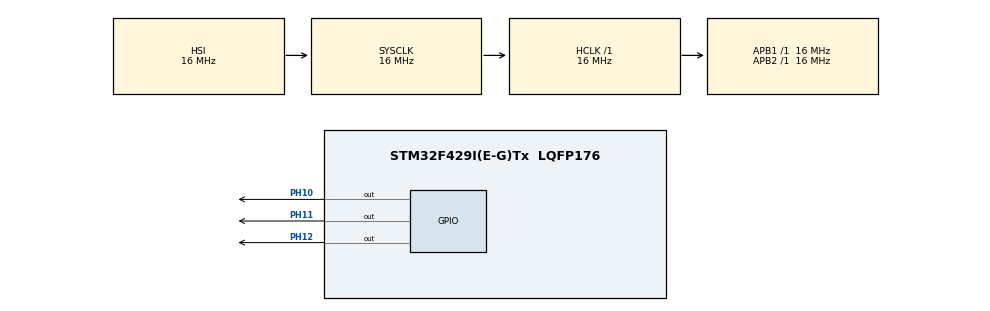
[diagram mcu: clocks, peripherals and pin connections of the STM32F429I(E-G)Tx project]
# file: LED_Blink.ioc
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Mcu.Family=STM32F4
Mcu.Name=STM32F429I(E-G)Tx
Mcu.Package=LQFP176
NVIC.PriorityGroup=NVIC_PRIORITYGROUP_4
PH10.Signal=GPIO_Output
PH11.Signal=GPIO_Output
PH12.Signal=GPIO_Output
ProjectManager.HeapSize=0x200
ProjectManager.StackSize=0x400
ProjectManager.TargetToolchain=STM32CubeIDE
RCC.AHBFreq_Value=16000000
RCC.APB1Freq_Value=16000000
RCC.APB2Freq_Value=16000000
RCC.CortexFreq_Value=16000000
RCC.HSE_VALUE=25000000
RCC.HSI_VALUE=16000000
RCC.LSE_VALUE=32768
RCC.SYSCLKFreq_VALUE=16000000
RCC.VCOOutputFreq_Value=192000000
board=custom

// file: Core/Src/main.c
/* USER CODE BEGIN Header */
/**
  ******************************************************************************
  * @file           : main.c
  * @brief          : Main program body
  ******************************************************************************
  * @attention
  *
  * Copyright (c) 2024 STMicroelectronics.
  * All rights reserved.
  *
  * This software is licensed under terms that can be found in the LICENSE file
  * in the root directory of this software component.
  * If no LICENSE file comes with this software, it is provided AS-IS.
  *
  ******************************************************************************
  */
/* USER CODE END Header */
#include "main.h"
#include "gpio.h"

/* USER CODE BEGIN PV */
uint32_t led1_cnt    = 0;
uint32_t led1_B      = 0;
uint32_t led1_isPlus = 0;

uint32_t led2_cnt    = 0;
uint32_t led2_B      = 0;
uint32_t led2_isPlus = 0;

uint32_t led3_cnt    = 0;
uint32_t led3_B      = 0;
uint32_t led3_isPlus = 0;

uint32_t delaycnt = 0;

/* USER CODE END PV */

void SystemClock_Config(void);

int main(void)
{

  /* MCU Configuration--------------------------------------------------------*/

  /* Reset of all peripherals, Initializes the Flash interface and the Systick. */
  HAL_Init();

  /* Configure the system clock */
  SystemClock_Config();

  /* Initialize all configured peripherals */
  MX_GPIO_Init();
  led1_B = 33;
  led2_B = 66;
  led3_B = 99;
  /* Infinite loop */
  while (1)
  {

    /* USER CODE BEGIN 3 */
	if(0) {
		HAL_GPIO_WritePin(GPIOH, GPIO_PIN_10, GPIO_PIN_RESET);
		HAL_Delay(50);
		HAL_GPIO_WritePin(GPIOH, GPIO_PIN_10, GPIO_PIN_SET);
		HAL_GPIO_WritePin(GPIOH, GPIO_PIN_11, GPIO_PIN_RESET);
		HAL_Delay(50);
		HAL_GPIO_WritePin(GPIOH, GPIO_PIN_11, GPIO_PIN_SET);
		HAL_GPIO_WritePin(GPIOH, GPIO_PIN_12, GPIO_PIN_RESET);
		HAL_Delay(50);
		HAL_GPIO_WritePin(GPIOH, GPIO_PIN_12, GPIO_PIN_SET);
	} else {
		//Xavier_Tsai
		delaycnt++;
		if(delaycnt>=1000) {
			delaycnt = 0;

			if(led1_isPlus) {
				//+
				led1_B++;
				if(led1_B>=100) {
					led1_isPlus = 0;
				}
			} else {
				//-
				led1_B--;
				if(led1_B<=0) {
					led1_isPlus = 1;
				}
			}

			if(led2_isPlus) {
				//+
				led2_B++;
				if(led2_B>=100) {
					led2_isPlus = 0;
				}
			} else {
				//-
				led2_B--;
				if(led2_B<=0) {
					led2_isPlus = 1;
				}
			}

			if(led3_isPlus) {
				//+
				led3_B++;
				if(led3_B>=100) {
					led3_isPlus = 0;
				}
			} else {
				//-
				led3_B--;
				if(led3_B<=0) {
					led3_isPlus = 1;
				}
			}
		}

		led1_cnt++;
		led2_cnt++;
		led3_cnt++;

		if(led1_cnt>=100) {
			led1_cnt = 0;
		}

		if(led2_cnt>=100) {
			led2_cnt = 0;
		}

		if(led3_cnt>=100) {
			led3_cnt = 0;
		}

		if(led1_cnt<led1_B) {
		    //LED ON
			HAL_GPIO_WritePin(GPIOH, GPIO_PIN_10, GPIO_PIN_RESET);
		} else {
			//LED OFF
			HAL_GPIO_WritePin(GPIOH, GPIO_PIN_10, GPIO_PIN_SET);
		}

		if(led2_cnt<led2_B) {
		    //LED ON
			HAL_GPIO_WritePin(GPIOH, GPIO_PIN_11, GPIO_PIN_RESET);
		} else {
			//LED OFF
			HAL_GPIO_WritePin(GPIOH, GPIO_PIN_11, GPIO_PIN_SET);
		}

		if(led3_cnt<led3_B) {
		    //LED ON
			HAL_GPIO_WritePin(GPIOH, GPIO_PIN_12, GPIO_PIN_RESET);
		} else {
			//LED OFF
			HAL_GPIO_WritePin(GPIOH, GPIO_PIN_12, GPIO_PIN_SET);
		}
	}

  }
  /* USER CODE END 3 */
}

void SystemClock_Config(void)
{
  RCC_OscInitTypeDef RCC_OscInitStruct = {0};
  RCC_ClkInitTypeDef RCC_ClkInitStruct = {0};

  /** Configure the main internal regulator output voltage
  */
  __HAL_RCC_PWR_CLK_ENABLE();
  __HAL_PWR_VOLTAGESCALING_CONFIG(PWR_REGULATOR_VOLTAGE_SCALE3);

  /** Initializes the RCC Oscillators according to the specified parameters
  * in the RCC_OscInitTypeDef structure.
  */
  RCC_OscInitStruct.OscillatorType = RCC_OSCILLATORTYPE_HSI;
  RCC_OscInitStruct.HSIState = RCC_HSI_ON;
  RCC_OscInitStruct.HSICalibrationValue = RCC_HSICALIBRATION_DEFAULT;
  RCC_OscInitStruct.PLL.PLLState = RCC_PLL_NONE;
  if (HAL_RCC_OscConfig(&RCC_OscInitStruct) != HAL_OK)
  {
    Error_Handler();
  }

  /** Initializes the CPU, AHB and APB buses clocks
  */
  RCC_ClkInitStruct.ClockType = RCC_CLOCKTYPE_HCLK|RCC_CLOCKTYPE_SYSCLK
                              |RCC_CLOCKTYPE_PCLK1|RCC_CLOCKTYPE_PCLK2;
  RCC_ClkInitStruct.SYSCLKSource = RCC_SYSCLKSOURCE_HSI;
  RCC_ClkInitStruct.AHBCLKDivider = RCC_SYSCLK_DIV1;
  RCC_ClkInitStruct.APB1CLKDivider = RCC_HCLK_DIV1;
  RCC_ClkInitStruct.APB2CLKDivider = RCC_HCLK_DIV1;

  if (HAL_RCC_ClockConfig(&RCC_ClkInitStruct, FLASH_LATENCY_0) != HAL_OK)
  {
    Error_Handler();
  }
}

void Error_Handler(void)
{
  __disable_irq();
  while (1)
  {
  }
}
